# MCU_NAVSS0_RINGACC0_UDMASS_RINGACC0_CFG_GCFG register map
Vendor: Texas Instruments
Peripheral module from a debugger description file (folder J7_AHP).
Registers are 32-bit, read-write, reset 0x0 unless marked. A register's access mark holds for its fields unless they carry their own. Offsets are as the file gives them; lines under a group give offsets from that group; [hi:lo] are bit positions; {n}, {i} and the like mark numbered series; 'fields as' and 'values as' point back to an identical list; <NAME> marks a mode.

## MCU_NAVSS0_RINGACC0_UDMASS_RINGACC0_CFG_GCFG
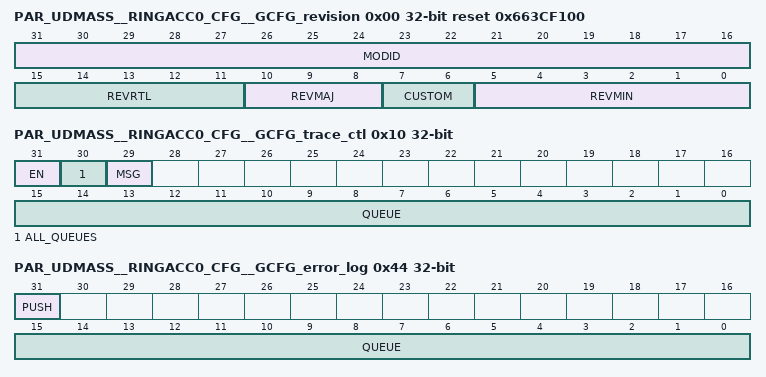
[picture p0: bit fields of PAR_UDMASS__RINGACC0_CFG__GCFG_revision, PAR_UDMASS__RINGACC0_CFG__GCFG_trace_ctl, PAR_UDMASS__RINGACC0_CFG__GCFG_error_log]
0x00 PAR_UDMASS__RINGACC0_CFG__GCFG_revision ro reset 0x663CF100
  [31:16] MODID — Module ID field
  [15:11] REVRTL — RTL revision. Will vary depending on release.
  [10:8] REVMAJ — Major revision
  [7:6] CUSTOM
  [5:0] REVMIN — Minor revision
0x10 PAR_UDMASS__RINGACC0_CFG__GCFG_trace_ctl
  [31] EN — Trace enable 0 = disable 1 = enable.
  [30] ALL_QUEUES — Trace everything 0 = only the selected queue 1 = every queue.
  [29] MSG — Trace message data 0 = include only the operation 1 = include message data.
  [15:0] QUEUE — Queue number when tracing a single queue.
0x20 PAR_UDMASS__RINGACC0_CFG__GCFG_overflow
  [15:0] QUEUE — Queue to send overflow messages. A value of 0xffff will disable the overflow function.
0x40 PAR_UDMASS__RINGACC0_CFG__GCFG_error_evt reset 0xFFFF
  [15:0] EVT — Event to send when detecting a bus error.
0x44 PAR_UDMASS__RINGACC0_CFG__GCFG_error_log ro
  [31] PUSH — Bus error was caused by a push. 0 = pop. 1 = push.
  [15:0] QUEUE — Queue that received the bus error.
